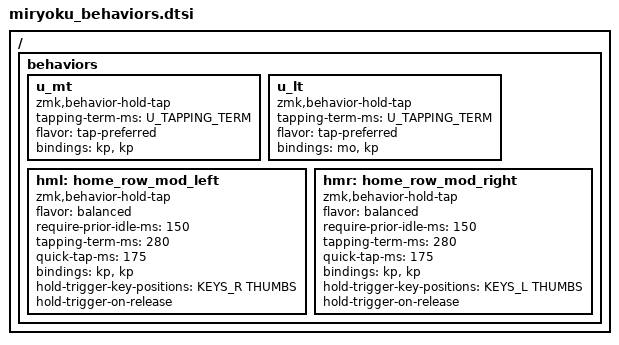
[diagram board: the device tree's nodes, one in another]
// Copyright 2022 Manna Harbour
// https://github.com/manna-harbour/miryoku

// Corne 42-key matrix positions (used by Chocofi with corne shield)
#define KEYS_L 0 1 2 3 4 5 12 13 14 15 16 17 24 25 26 27 28 29
#define KEYS_R 6 7 8 9 10 11 18 19 20 21 22 23 30 31 32 33 34 35
#define THUMBS 36 37 38 39 40 41

/ {
  behaviors {
    u_mt: u_mt {
      compatible = "zmk,behavior-hold-tap";
      #binding-cells = <2>;
      tapping-term-ms = <U_TAPPING_TERM>;
      flavor = "tap-preferred";
      bindings = <&kp>, <&kp>;
    };
    u_lt: u_lt {
      compatible = "zmk,behavior-hold-tap";
      #binding-cells = <2>;
      tapping-term-ms = <U_TAPPING_TERM>;
      flavor = "tap-preferred";
      bindings = <&mo>, <&kp>;
    };
    hml: home_row_mod_left {
      compatible = "zmk,behavior-hold-tap";
      #binding-cells = <2>;
      flavor = "balanced";
      require-prior-idle-ms = <150>;
      tapping-term-ms = <280>;
      quick-tap-ms = <175>;
      bindings = <&kp>, <&kp>;
      hold-trigger-key-positions = <KEYS_R THUMBS>;
      hold-trigger-on-release;
    };
    hmr: home_row_mod_right {
      compatible = "zmk,behavior-hold-tap";
      #binding-cells = <2>;
      flavor = "balanced";
      require-prior-idle-ms = <150>;
      tapping-term-ms = <280>;
      quick-tap-ms = <175>;
      bindings = <&kp>, <&kp>;
      hold-trigger-key-positions = <KEYS_L THUMBS>;
      hold-trigger-on-release;
    };
  };
};
